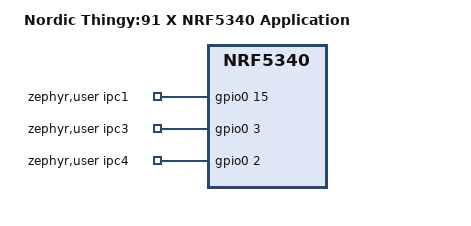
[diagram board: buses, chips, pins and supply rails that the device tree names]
/*
 * Copyright (c) 2024 Nordic Semiconductor
 * SPDX-License-Identifier: LicenseRef-Nordic-5-Clause
 */

/dts-v1/;
#include <nordic/nrf5340_cpuapp_qkaa.dtsi>
#include "kestrel_nrf5340_cpuapp_common.dts"

/ {
	model = "Nordic Thingy:91 X NRF5340 Application";
	compatible = "nordic,kestrel-nrf5340-cpuapp";
	
	chosen {
		zephyr,sram = &sram0_image;
		zephyr,flash = &flash0;
		zephyr,code-partition = &slot0_partition;
		zephyr,sram-secure-partition = &sram0_s;
		zephyr,sram-non-secure-partition = &sram0_ns;
		zephyr,bt-hci = &bt_hci_ipc0;
	};


	zephyr,user {
		ipc1-gpios = <&gpio0 15 0>;
		ipc3-gpios = <&gpio0 3 0>;
		ipc4-gpios = <&gpio0 2 0>;
	};


};
